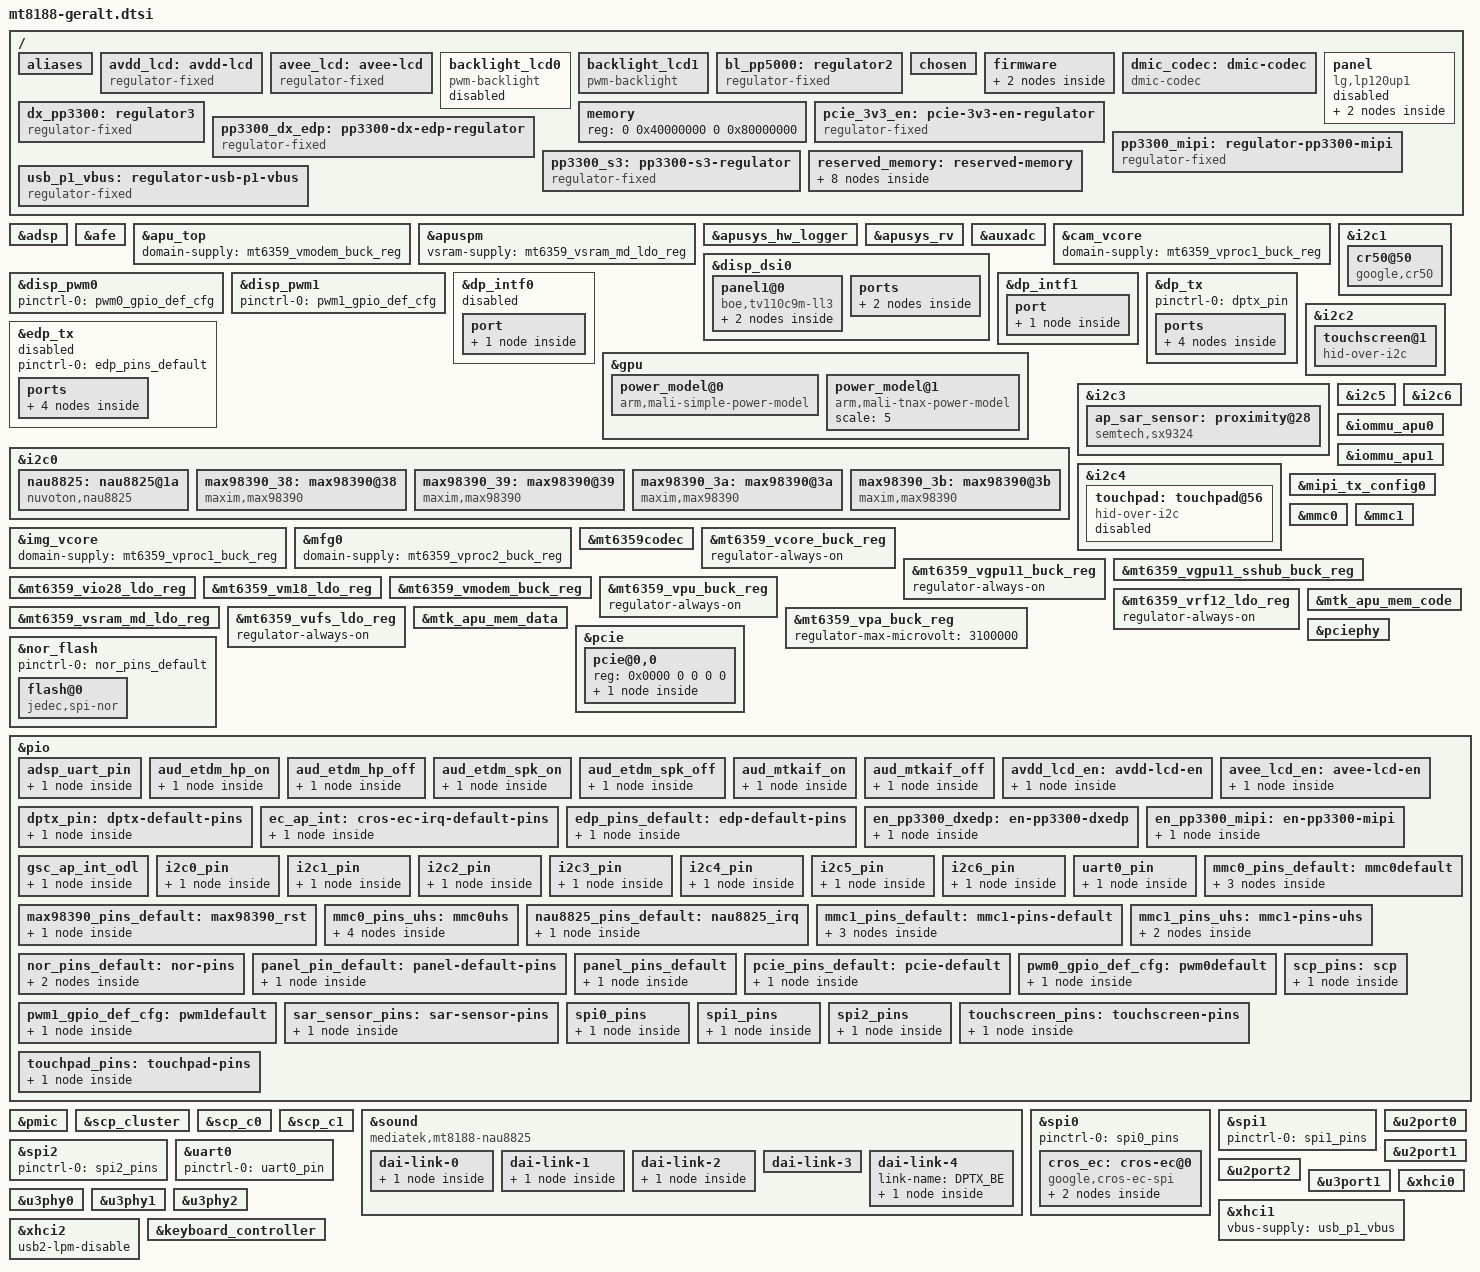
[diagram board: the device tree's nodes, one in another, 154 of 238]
// SPDX-License-Identifier: (GPL-2.0 OR MIT)
/*
 * Copyright (C) 2022 MediaTek Inc.
 */
/dts-v1/;
#include <dt-bindings/gpio/gpio.h>
#include "mt8188.dtsi"
#include "mt6359.dtsi"

/ {
	aliases {
		serial0 = &uart0;
		i2c0 = &i2c0;
		i2c1 = &i2c1;
		i2c2 = &i2c2;
		i2c3 = &i2c3;
		i2c4 = &i2c4;
		i2c5 = &i2c5;
		i2c6 = &i2c6;
		mmc0 = &mmc0;
		mmc1 = &mmc1;
	};

	avdd_lcd: avdd-lcd {
		compatible = "regulator-fixed";
		regulator-name = "avdd_lcd";
		gpio = <&pio 3 GPIO_ACTIVE_HIGH>;
		enable-active-high;
		pinctrl-names = "default";
		pinctrl-0 = <&avdd_lcd_en>;
	};

	avee_lcd: avee-lcd {
		compatible = "regulator-fixed";
		regulator-name = "avee_lcd";
		gpio = <&pio 4 GPIO_ACTIVE_HIGH>;
		enable-active-high;
		pinctrl-names = "default";
		pinctrl-0 = <&avee_lcd_en>;
		regulator-enable-ramp-delay = <10000>;
	};

	backlight_lcd0: backlight_lcd0 {
		compatible = "pwm-backlight";
		pwms = <&disp_pwm1 0 500000>;
		power-supply = <&bl_pp5000>;
		enable-gpios = <&pio 110 0>;
		brightness-levels = <0 1023>;
		num-interpolated-steps = <1023>;
		default-brightness-level = <576>;
		status = "disabled";
	};

	backlight_lcd1: backlight_lcd1 {
		compatible = "pwm-backlight";
		pwms = <&disp_pwm0 0 500000>;
		power-supply = <&bl_pp5000>;
		enable-gpios = <&pio 1 0>;
		brightness-levels = <0 1023>;
		num-interpolated-steps = <1023>;
		default-brightness-level = <576>;
		status = "okay";
	};

	bl_pp5000: regulator2 {
		compatible = "regulator-fixed";
		regulator-name = "bl_pp5000";
		regulator-min-microvolt = <5000000>;
		regulator-max-microvolt = <5000000>;
		regulator-always-on;
		regulator-boot-on;
		enable-active-high;
	};

	/* chosen */
	chosen: chosen {
		stdout-path = "serial0:115200n8";
		kaslr-seed = <0 0>;
	};

	firmware {
		optee {
			compatible = "linaro,optee-tz";
			method = "smc";
			interrupt-parent = <&gic>;
			interrupts = <GIC_SPI 547 IRQ_TYPE_LEVEL_HIGH 0>;
		};

		mtk_svp_heap {
			compatible = "mediatek,secure_heap";
			memory-region = <&secure_cma_reserved>;
		};
	};

        dmic_codec: dmic-codec {
		compatible = "dmic-codec";
		num-channels = <2>;
		wakeup-delay-ms = <50>;
	};

	dx_pp3300: regulator3 {
		compatible = "regulator-fixed";
		regulator-name = "dx_pp3300";
		regulator-min-microvolt = <3300000>;
		regulator-max-microvolt = <3300000>;
		regulator-always-on;
		regulator-boot-on;
		enable-active-high;
	};

	memory {
		device_type = "memory";
		reg = <0 0x40000000 0 0x80000000>;
	};

	panel: panel {
		compatible = "lg,lp120up1";
		status = "disabled";
		pinctrl-names = "default";
		pinctrl-0 = <&panel_pin_default>;
		backlight = <&backlight_lcd0>;
		port {
			panel_in: endpoint {
				remote-endpoint = <&edp_out>;
			};
		};
	};

	pcie_3v3_en: pcie-3v3-en-regulator {
		compatible = "regulator-fixed";
		regulator-name = "pcie_3v3_en";
		regulator-always-on;
		gpio = <&pio 12 0>;
		enable-active-high;
	};

	pp3300_dx_edp: pp3300-dx-edp-regulator {
		compatible = "regulator-fixed";
		regulator-name = "pp3300_dx_edp";
		pinctrl-names = "default";
		pinctrl-0 = <&en_pp3300_dxedp>;
		enable-active-high;
		regulator-boot-on;
		gpio = <&pio 27 GPIO_ACTIVE_HIGH>;
		vin-supply = <&dx_pp3300>;
	};

	pp3300_mipi: regulator-pp3300-mipi {
		compatible = "regulator-fixed";
		regulator-name = "pp3300_mipi";
		regulator-min-microvolt = <3300000>;
		regulator-max-microvolt = <3300000>;
		regulator-always-on;
		regulator-boot-on;
		enable-active-high;
	};

	pp3300_s3: pp3300-s3-regulator {
		compatible = "regulator-fixed";
		regulator-name = "pp3300_s3";
		pinctrl-names = "default";
		pinctrl-0 = <&en_pp3300_mipi>;
		enable-active-high;
		regulator-boot-on;
		gpio = <&pio 144 GPIO_ACTIVE_HIGH>;
		vin-supply = <&pp3300_mipi>;
	};

	/*
	 * The reserved memory space address and size MUST be in line with the
	 * EMI PMU configuration in the firmware.
	 */
	reserved_memory: reserved-memory {
		#address-cells = <2>;
		#size-cells = <2>;
		ranges;

		scp_mem_reserved: scp_mem_region {
			compatible = "shared-dma-pool";
			reg = <0 0x50000000 0 0x800000>;
			no-map;
		};

		apu_reserve_memory: apu-reserve-memory {
			compatible = "shared-dma-pool";
			reg = <0 0x55000000 0 0x1400000>;
		};

		adsp_mem_reserved: adsp_mem_region {
			compatible = "mediatek,adsp-reserved-memory";
			reg = <0 0x60000000 0 0xF00000>;
			no-map;
		};

		afe_dma_mem_reserved: snd_dma_mem_region {
			compatible = "shared-dma-pool";
			reg = <0 0x60F00000 0 0x100000>;
			no-map;
		};

		adsp_dma_mem_reserved: adsp_dma_mem_region {
			compatible = "shared-dma-pool";
			reg = <0 0x61000000 0 0x100000>;
			no-map;
		};

		scp_dual_mem_reserved: scp-dual-mem-region {
			compatible = "shared-dma-pool";
			reg = <0 0x70000000 0 0x0A000000>;
			no-map;
		};

		scp_isp_cma_reserved: scp-isp-cma-region {
			compatible = "shared-dma-pool";
			reg = <0 0x7A000000 0 0x05000000>;
			reusable;
		};

		secure_cma_reserved: secure_cma_region {
			compatible = "mediatek,dynamic-restricted-region";
			reg = <0 0x7F000000 0 0x400000>;
			reusable;
		};
	};

	usb_p1_vbus: regulator-usb-p1-vbus {
		compatible = "regulator-fixed";
		regulator-name = "vbus0";
		regulator-min-microvolt = <5000000>;
		regulator-max-microvolt = <5000000>;
		enable-active-high;
		gpio = <&pio 150 GPIO_ACTIVE_HIGH>;
	};
};

&adsp {
	memory-region = <&adsp_dma_mem_reserved>,
		<&adsp_mem_reserved>;
	pinctrl-names = "default";
	pinctrl-0 = <&adsp_uart_pin>;
	status = "okay";
};

&afe {
	memory-region = <&afe_dma_mem_reserved>;
	mediatek,etdm-out1-cowork-source = <0>; /* in1 */
	mediatek,etdm-in2-cowork-source = <3>; /* out2 */
	status = "okay";
};

&apu_top {
	domain-supply = <&mt6359_vmodem_buck_reg>;
};

&apuspm {
	vsram-supply = <&mt6359_vsram_md_ldo_reg>;
	status = "okay";
};

&apusys_hw_logger {
	status = "okay";
};

&apusys_rv {
	status = "okay";
};

&auxadc {
	status = "okay";
};

&cam_vcore {
	domain-supply = <&mt6359_vproc1_buck_reg>;
};

&disp_dsi0 {
	#address-cells = <1>;
	#size-cells = <0>;
	status = "okay";

	panel1@0 {
		compatible = "boe,tv110c9m-ll3";
		reg = <0>;
		enable-gpios = <&pio 25 0>;
		avdd-supply = <&avdd_lcd>;
		avee-supply = <&avee_lcd>;
		pinctrl-names = "default";
		pinctrl-0 = <&panel_pins_default>;
		pp1800-supply = <&mt6359_vm18_ldo_reg>;
		backlight = <&backlight_lcd1>;
		rotation = <270>;
		status = "okay";

		port {
			panel1_in: endpoint {
				remote-endpoint = <&dsi_out>;
			};
		};
	};

	ports {
		port {
			dsi_out: endpoint {
				remote-endpoint = <&panel1_in>;
			};
		};
	};
};

&disp_pwm0 {
	pinctrl-names = "default";
	pinctrl-0 = <&pwm0_gpio_def_cfg>;
	status = "okay";
};

&disp_pwm1 {
	pinctrl-names = "default";
	pinctrl-0 = <&pwm1_gpio_def_cfg>;
	status = "okay";
};

&dp_intf0 {
	status = "disabled";

	port {
		dp_intf0_out: endpoint {
			remote-endpoint = <&edp_in>;
		};
	};
};

&dp_intf1 {
	status = "okay";

	port {
		dp_intf1_out: endpoint {
			remote-endpoint = <&dptx_in>;
		};
	};
};

&dp_tx {
	status = "okay";

	pinctrl-names = "default";
	pinctrl-0 = <&dptx_pin>;

	ports {
		#address-cells = <1>;
		#size-cells = <0>;

		port@0 {
			reg = <0>;
			dptx_in: endpoint {
				remote-endpoint = <&dp_intf1_out>;
			};
		};

		port@1 {
			reg = <1>;
			dptx_out: endpoint {
				data-lanes = <0 1 2 3>;
			};
		};
	};
};

&edp_tx {
	status = "disabled";

	pinctrl-names = "default";
	pinctrl-0 = <&edp_pins_default>;

	ports {
		#address-cells = <1>;
		#size-cells = <0>;

		port@0 {
			reg = <0>;
			edp_in: endpoint {
				remote-endpoint = <&dp_intf0_out>;
			};
		};

		port@1 {
			reg = <1>;
			edp_out: endpoint {
				remote-endpoint = <&panel_in>;
				data-lanes = <0 1 2 3>;
			};
		};
	};
};

&gpu {
	supply-names = "mali","mali_sram";
	mali-supply = <&mt6359_vproc2_buck_reg>;
	mali_sram-supply = <&mt6359_vsram_others_ldo_reg>;
	operating-points-v2 = <&gpu_opp_table>;
	volt-bin-mapping = <3 4 5 6>;

	power_model@0 {
		compatible = "arm,mali-simple-power-model";
		static-coefficient = <2427750>;
		dynamic-coefficient = <4687>;
		ts = <20000 2000 (-20) 2>;
		thermal-zone = "soc_max";
	};

	power_model@1 {
		compatible = "arm,mali-tnax-power-model";
		scale = <5>;
	};
};

&i2c0 {
	pinctrl-names = "default";
	pinctrl-0 = <&i2c0_pin>;
	clock-frequency = <400000>;
	status = "okay";

	nau8825: nau8825@1a {
		#sound-dai-cells = <0>;
		compatible = "nuvoton,nau8825";
		reg = <0x1a>;
		interrupt-parent = <&pio>;
		interrupts = <108 IRQ_TYPE_LEVEL_LOW>;
		pinctrl-names = "default";
		pinctrl-0 = <&nau8825_pins_default>;

		nuvoton,jkdet-enable;
		nuvoton,jkdet-polarity = <1>;
		nuvoton,vref-impedance = <2>;
		nuvoton,micbias-voltage = <6>;
		nuvoton,sar-hysteresis = <1>;
		nuvoton,sar-voltage = <6>;
		nuvoton,sar-compare-time = <0>;
		nuvoton,sar-sampling-time = <0>;
		nuvoton,short-key-debounce = <2>;
		nuvoton,jack-insert-debounce = <7>;
		nuvoton,jack-eject-debounce = <7>;
		nuvoton,adc-delay-ms = <300>;
		status = "okay";
	};

	max98390_38: max98390@38 {
		#sound-dai-cells = <0>;
		compatible = "maxim,max98390";
		reg = <0x38>;
		sound-name-prefix = "Rear Right";
		reset-gpios = <&pio 118 1>;
		pinctrl-names = "default";
		pinctrl-0 = <&max98390_pins_default>;
		status = "okay";
	};

	max98390_39: max98390@39 {
		#sound-dai-cells = <0>;
		compatible = "maxim,max98390";
		reg = <0x39>;
		sound-name-prefix = "Rear Left";
		status = "okay";
	};

	max98390_3a: max98390@3a {
		#sound-dai-cells = <0>;
		compatible = "maxim,max98390";
		reg = <0x3A>;
		sound-name-prefix = "Front Left";
		status = "okay";
	};

	max98390_3b: max98390@3b {
		#sound-dai-cells = <0>;
		compatible = "maxim,max98390";
		reg = <0x3B>;
		sound-name-prefix = "Front Right";
		status = "okay";
	};
};

&i2c1 {
	pinctrl-names = "default";
	pinctrl-0 = <&i2c1_pin>;
	clock-frequency = <400000>;
	status = "okay";

	cr50@50 {
		compatible = "google,cr50";
		reg = <0x50>;
		interrupt-parent = <&pio>;
		interrupts = <0 IRQ_TYPE_EDGE_RISING>;
		pinctrl-names = "default";
		pinctrl-0 = <&gsc_ap_int_odl>;
	};
};

&i2c2 {
	pinctrl-names = "default";
	pinctrl-0 = <&i2c2_pin>;
	clock-frequency = <400000>;
	status = "okay";

	touchscreen@1 {
		status = "okay";
		compatible = "hid-over-i2c";
		reg = <0x1>;
		interrupt-parent = <&pio>;
		interrupts = <143 IRQ_TYPE_EDGE_FALLING>;
		pinctrl-names = "default";
		pinctrl-0 = <&touchscreen_pins>;
		vdd-supply = <&pp3300_s3>;
		vddl-supply = <&mt6359_vm18_ldo_reg>;
		post-power-on-delay-ms = <500>;
		hid-descr-addr = <0x0001>;
	};
};

&i2c3 {
	pinctrl-names = "default";
	pinctrl-0 = <&i2c3_pin>;
	clock-frequency = <400000>;
	status = "okay";

	ap_sar_sensor: proximity@28 {
		compatible = "semtech,sx9324";
		reg = <0x28>;
		#io-channel-cells = <1>;
		pinctrl-names = "default";
		pinctrl-0 = <&sar_sensor_pins>;
		interrupt-parent = <&pio>;
		interrupts = <88 IRQ_TYPE_LEVEL_LOW>;
		vdd-supply = <&mt6359_vio18_ldo_reg>;
		svdd-supply = <&mt6359_vio18_ldo_reg>;
	};
};

&i2c4 {
	pinctrl-names = "default";
	pinctrl-0 = <&i2c4_pin>;
	clock-frequency = <400000>;
	status = "okay";

	touchpad: touchpad@56 {
		status = "disabled";
		compatible = "hid-over-i2c";
		reg = <0x56>;
		interrupt-parent = <&pio>;
		interrupts = <148 IRQ_TYPE_LEVEL_LOW>;
		pinctrl-names = "default";
		pinctrl-0 = <&touchpad_pins>;
		hid-descr-addr = <0x0001>;
		wakeup-source;
	};
};

&i2c5 {
	pinctrl-names = "default";
	pinctrl-0 = <&i2c5_pin>;
	clock-frequency = <400000>;
	status = "okay";
};

&i2c6 {
	pinctrl-names = "default";
	pinctrl-0 = <&i2c6_pin>;
	clock-frequency = <400000>;
	status = "okay";
};

&img_vcore {
	domain-supply = <&mt6359_vproc1_buck_reg>;
};

&iommu_apu0 {
	status = "okay";
};

&iommu_apu1 {
	status = "okay";
};

&mfg0 {
	domain-supply = <&mt6359_vproc2_buck_reg>;
};

&mipi_tx_config0 {
	status = "okay";
};

&mmc0 {
	status = "okay";
	pinctrl-names = "default", "state_uhs";
	pinctrl-0 = <&mmc0_pins_default>;
	pinctrl-1 = <&mmc0_pins_uhs>;
	bus-width = <8>;
	max-frequency = <200000000>;
	cap-mmc-highspeed;
	mmc-hs200-1_8v;
	mmc-hs400-1_8v;
	supports-cqe;
	cap-mmc-hw-reset;
	no-sdio;
	no-sd;
	hs400-ds-delay = <0x1481b>;
	vmmc-supply = <&mt6359_vemc_1_ldo_reg>;
	vqmmc-supply = <&mt6359_vufs_ldo_reg>;
	non-removable;
};

&mmc1 {
	status = "okay";
	pinctrl-names = "default", "state_uhs";
	pinctrl-0 = <&mmc1_pins_default>;
	pinctrl-1 = <&mmc1_pins_uhs>;
	bus-width = <4>;
	max-frequency = <200000000>;
	cap-sd-highspeed;
	sd-uhs-sdr50;
	sd-uhs-sdr104;
	no-mmc;
	no-sdio;
	cd-gpios = <&pio 107 GPIO_ACTIVE_LOW>;
	vmmc-supply = <&mt6359_vpa_buck_reg>;
	vqmmc-supply = <&mt6359_vsim1_ldo_reg>;
};

&mt6359codec {
	mediatek,dmic-mode = <1>; /* one-wire */
	mediatek,mic-type-0 = <2>; /* DMIC */
	mediatek,mic-type-2 = <2>; /* DMIC */
};

&mt6359_vcore_buck_reg {
	regulator-always-on;
};

&mt6359_vgpu11_buck_reg {
	regulator-always-on;
};

&mt6359_vgpu11_sshub_buck_reg {
	regulator-always-on;
	regulator-min-microvolt = <550000>;
	regulator-max-microvolt = <550000>;
};

&mt6359_vio28_ldo_reg {
	/delete-property/ regulator-always-on;
};

&mt6359_vm18_ldo_reg {
	/delete-property/ regulator-always-on;
};

&mt6359_vmodem_buck_reg {
	regulator-min-microvolt = <775000>;
	regulator-max-microvolt = <775000>;
};

&mt6359_vpu_buck_reg {
	regulator-always-on;
};

&mt6359_vrf12_ldo_reg {
	regulator-always-on;
};

&mt6359_vsram_md_ldo_reg {
	regulator-min-microvolt = <800000>;
	regulator-max-microvolt = <800000>;
};

&mt6359_vufs_ldo_reg {
	regulator-always-on;
};

&mt6359_vpa_buck_reg {
	regulator-max-microvolt = <3100000>;
};

&mtk_apu_mem_code {
	status = "okay";
};

&mtk_apu_mem_data {
	status = "okay";
};

&nor_flash {
	status = "okay";
	pinctrl-names = "default";
	pinctrl-0 = <&nor_pins_default>;

	flash@0 {
		compatible = "jedec,spi-nor";
		reg = <0>;
		spi-max-frequency = <52000000>;
	};
};

&pcie {
	pinctrl-names = "default";
	pinctrl-0 = <&pcie_pins_default>;
	pcie3v3-supply = <&pcie_3v3_en>;
	pcie1v8-supply = <&mt6359_vcn18_ldo_reg>;
	dsc-reset-gpios = <&pio 145 1>;
	status = "okay";

	pcie@0,0 {
		#address-cells = <3>;
		#size-cells = <2>;
		reg = <0x0000 0 0 0 0>;
		wifi: pcie@1,0 {
			reg = <0x0000 0 0 0 0>;
			wakeup-source;
		};
	};
};

&pciephy {
	status = "okay";
};

&pio {
	pinctrl-names = "default";

	gpio-line-names =
		"GSC_AP_INT_ODL",
		"AP_DISP_BKLTEN",
		"",
		"EN_PPVAR_MIPI_DISP",
		"EN_PPVAR_MIPI_DISP_150MA",
		"TCHSCR_RST_1V8_L",
		"TCHSRC_REPORT_DISABLE",
		"",
		"",
		"",
		"",
		"I2S_SPKR_DATAOUT",
		"EN_PP3300_WLAN_X",
		"WIFI_KILL_1V8_L",
		"BT_KILL_1V8_L",
		"AP_FLASH_WP_L",
		"",
		"EDP_HDP_1V8",
		"WCAM_PWDN_L",
		"WCAM_RST_L",
		"UCAM_PWDM_L",
		"UCAM_RST_L",
		"WCAM_24M_CLK",
		"UCAM_24M_CLK",
		"MT6319_INT",
		"DISP_RST_1V8_L",
		"DSIO_DSI_TE",
		"EN_PP3300_EDP_DISP_X",
		"TP",
		"MIPI_BL_PWM_1V8",
		"EDP_BL_PWM_1V8",
		"UART_AP_TX_GSC_RX",
		"UART_GSC_TX_AP_RX",
		"UART_SSPM_TX_DBGCON_RX",
		"UART_DBGCON_TX_SSPM_RX",
		"UART_ADSP_TX_DBGCON_RX",
		"UART_DBGCON_TX_ADSP_RX",
		"JTAG_AP_TMS",
		"JTAG_AP_TCK",
		"JTAG_AP_TDI",
		"JTAG_AP_TDO",
		"JTAG_AP_TRST",
		"AP_KPCOLO",
		"TP",
		"BEEP_ON_OD",
		"TP",
		"EC_AP_HPD_OD",
		"PCIE_WAKE_1V8_ODL",
		"PCIE_RST_1V8_L",
		"PCIE_CLKREQ_1V8_ODL",
		"MIPI_DISP_ID0",
		"MIPI_DISP_ID1",
		"",
		"",
		"",
		"AP_I2C_AUD_SCL_1V8",
		"AP_I2C_AUD_SDA_1V8",
		"AP_I2C_TPM_SCL_1V8",
		"AP_I2C_TPM_SDA_1V8",
		"AP_I2C_TCHSCR_SCL_1V8",
		"AP_I2C_TCHSCR_SDA_1V8",
		"AP_I2C_PMIC_SAR_SCL_1V8",
		"AP_I2C_PMIC_SAR_SDA_1V8",
		"AP_I2C_EC_HID_KB_SCL_1V8",
		"AP_I2C_EC_HID_KB_SDA_1V8",
		"AP_I2C_UCAM_SCL_1V8",
		"AP_I2C_UCAM_SDA_1V8",
		"AP_I2C_WCAM_SCL_1V8",
		"AP_I2C_WCAM_SDA_1V8",
		"SPI_AP_CS_EC_L",
		"SPI_AP_CLK_EC",
		"SPI_AP_DO_EC_DI",
		"SPI_AP_DI_EC_DO",
		"TP",
		"TP",
		"SPI_AP_CS_TCHSCR_L",
		"SPI_AP_CLK_TCHSCR",
		"SPI_AP_DO_TCHSCR_DI",
		"SPI_AP_DI_TCHSCR_DO",
		"TP",
		"TP",
		"TP",
		"TP",
		"",
		"",
		"",
		"TP",
		"",
		"SAR_INT_ODL",
		"",
		"",
		"",
		"PWRAP_SPI_CS_L",
		"PWRAP_SPI_CK",
		"PWRAP_SPI_MOSI",
		"PWRAP_SPI_MISO",
		"SRCLKENA0",
		"SRCLKENA1",
		"SCP_VREQ_VAO",
		"AP_RTC_CLK32K",
		"AP_PMIC_WDTRST_L",
		"AUD_CLK_MOSI",
		"AUD_SYNC_MOSI",
		"AUD_DAT_MOSI0",
		"AUD_DAT_MOSI1",
		"AUD_DAT_MISO0",
		"AUD_DAT_MISO1",
		"SD_CD_ODL",
		"HP_INT_ODL",
		"SPKR_INT_ODL",
		"I2S_HP_DATAIN",
		"EN_SPKR",
		"I2S_SPKR_MCLK",
		"I2S_SPKR_BCLK",
		"I2S_HP_MCLK",
		"I2S_HP_BCLK",
		"I2S_HP_LRCK",
		"I2S_HP_DATAOUT",
		"RST_SPKR_L",
		"I2S_SPKR_LRCK",
		"I2S_SPKR_DATAIN",
		"",
		"",
		"",
		"",
		"SPI_AP_CLK_ROM",
		"SPI_AP_CS_ROM_L",
		"SPI_AP_DO_ROM_DI",
		"SPI_AP_DI_ROM_DO",
		"TP",
		"TP",
		"",
		"",
		"",
		"",
		"",
		"",
		"",
		"",
		"EN_PP2800A_UCAM_X",
		"EN_PP1200_UCAM_X",
		"EN_PP2800A_WCAM_X",
		"EN_PP1100_WCAM_X",
		"TCHSCR_INI_1V8_L",
		"EN_PP300_MIPI_TCHSRC_X",
		"MT7921_PMU_EN_1V8",
		"EN_PP3300_EDP_TCHSCR_X",
		"AP_EC_WARM_RST_REQ",
		"EC_AP_HID_INT_ODL",
		"EC_AP_INT_ODL",
		"AP_XHCI_INIT_DONE",
		"EMMC_DAT7",
		"EMMC_DAT6",
		"EMMC_DAT5",
		"EMMC_DAT4",
		"EMMC_RST_L",
		"EMMC_CMD",
		"EMMC_CLK",
		"EMMC_DAT3",
		"EMMC_DAT2",
		"EMMC_DAT1",
		"EMMC_DAT0",
		"EMMC_DSL",
		"SD_CMD",
		"SD_CLK",
		"SD_DAT0",
		"SD_DAT1",
		"SD_DAT2",
		"SD_DAT3",
		"",
		"",
		"USB3_HUB_RST_L",
		"EC_AP_RSVD0_ODL",
		"",
		"",
		"SPMI_SCL",
		"SPMI_SDA";

	adsp_uart_pin: adsp_uart_pin {
		adsp_uart_pins {
			pinmux = <PINMUX_GPIO35__FUNC_O_ADSP_UTXD0>,
				 <PINMUX_GPIO36__FUNC_I1_ADSP_URXD0>;
		};
	};

	aud_etdm_hp_on: aud_etdm_hp_on {
		pins-cmd-dat {
			pinmux = <PINMUX_GPIO110__FUNC_I0_I2SIN_D0>,
				 <PINMUX_GPIO115__FUNC_B0_I2SO2_BCK>,
				 <PINMUX_GPIO116__FUNC_B0_I2SO2_WS>,
				 <PINMUX_GPIO117__FUNC_O_I2SO2_D0>;
		};
	};

	aud_etdm_hp_off: aud_etdm_hp_off {
		pins-cmd-dat {
			pinmux = <PINMUX_GPIO110__FUNC_B_GPIO110>,
				 <PINMUX_GPIO115__FUNC_B_GPIO115>,
				 <PINMUX_GPIO116__FUNC_B_GPIO116>,
				 <PINMUX_GPIO117__FUNC_B_GPIO117>;
			bias-pull-down;
			input-enable;
		};
	};

	aud_etdm_spk_on: aud_etdm_spk_on {
		pins-cmd-dat {
			pinmux = <PINMUX_GPIO11__FUNC_O_I2SO1_D0>,
				 <PINMUX_GPIO113__FUNC_B0_TDMIN_BCK>,
				 <PINMUX_GPIO119__FUNC_B0_TDMIN_LRCK>,
				 <PINMUX_GPIO120__FUNC_I0_TDMIN_DI>;
		};
	};

	aud_etdm_spk_off: aud_etdm_spk_off {
		pins-cmd-dat {
			pinmux = <PINMUX_GPIO11__FUNC_B_GPIO11>,
				 <PINMUX_GPIO113__FUNC_B_GPIO113>,
				 <PINMUX_GPIO119__FUNC_B_GPIO119>,
				 <PINMUX_GPIO120__FUNC_B_GPIO120>;
			bias-pull-down;
			input-enable;
		};
	};

	aud_mtkaif_on: aud_mtkaif_on {
		pins_cmd_dat {
			pinmux = <PINMUX_GPIO101__FUNC_O_AUD_CLK_MOSI>,
				 <PINMUX_GPIO102__FUNC_O_AUD_SYNC_MOSI>,
				 <PINMUX_GPIO103__FUNC_O_AUD_DAT_MOSI0>,
				 <PINMUX_GPIO104__FUNC_O_AUD_DAT_MOSI1>,
				 <PINMUX_GPIO105__FUNC_I0_AUD_DAT_MISO0>,
				 <PINMUX_GPIO106__FUNC_I0_AUD_DAT_MISO1>;
		};
	};

	aud_mtkaif_off: aud_mtkaif_off {
		pins_cmd_dat {
			pinmux = <PINMUX_GPIO101__FUNC_B_GPIO101>,
				 <PINMUX_GPIO102__FUNC_B_GPIO102>,
				 <PINMUX_GPIO103__FUNC_B_GPIO103>,
				 <PINMUX_GPIO104__FUNC_B_GPIO104>,
				 <PINMUX_GPIO105__FUNC_B_GPIO105>,
				 <PINMUX_GPIO106__FUNC_B_GPIO106>;
			bias-pull-down;
			input-enable;
		};
	};

	avdd_lcd_en: avdd-lcd-en {
		pins1 {
			pinmux = <PINMUX_GPIO3__FUNC_B_GPIO3>;
			output-low;
		};
	};

	avee_lcd_en: avee-lcd-en {
		pins1 {
			pinmux = <PINMUX_GPIO4__FUNC_B_GPIO4>;
			output-low;
		};
	};

	dptx_pin: dptx-default-pins {
		pins-cmd-dat {
			pinmux = <PINMUX_GPIO46__FUNC_I0_DP_TX_HPD>;
		};
	};

	ec_ap_int: cros-ec-irq-default-pins {
		pins1 {
			pinmux = <PINMUX_GPIO149__FUNC_B_GPIO149>;
			input-enable;
		};
	};

	edp_pins_default: edp-default-pins {
		pins-cmd-dat {
			pinmux = <PINMUX_GPIO17__FUNC_I0_EDP_TX_HPD>;
		};
	};

	en_pp3300_dxedp: en-pp3300-dxedp {
		pins1 {
			pinmux = <PINMUX_GPIO27__FUNC_B_GPIO27>;
			output-low;
		};
	};

	en_pp3300_mipi: en-pp3300-mipi {
		pins1 {
			pinmux = <PINMUX_GPIO144__FUNC_B_GPIO144>;
			output-low;
		};
	};

	gsc_ap_int_odl: gsc_ap_int_odl {
		pin {
			pinmux = <PINMUX_GPIO0__FUNC_B_GPIO0>;
			input-enable;
		};
	};

	i2c0_pin: i2c0_pin {
		pins_bus {
			pinmux = <PINMUX_GPIO56__FUNC_B1_SDA0>,
				 <PINMUX_GPIO55__FUNC_B1_SCL0>;
		};
	};

	i2c1_pin: i2c1_pin {
		pins_bus {
			pinmux = <PINMUX_GPIO58__FUNC_B1_SDA1>,
				 <PINMUX_GPIO57__FUNC_B1_SCL1>;
		};
	};

	i2c2_pin: i2c2_pin {
		pins_bus {
			pinmux = <PINMUX_GPIO60__FUNC_B1_SDA2>,
				 <PINMUX_GPIO59__FUNC_B1_SCL2>;
			bias-disable;
			drive-strength = <MTK_DRIVE_12mA>;
		};
	};

	i2c3_pin: i2c3_pin {
		pins_bus {
			pinmux = <PINMUX_GPIO62__FUNC_B1_SDA3>,
				 <PINMUX_GPIO61__FUNC_B1_SCL3>;
		};
	};

	i2c4_pin: i2c4_pin {
		pins_bus {
			pinmux = <PINMUX_GPIO64__FUNC_B1_SDA4>,
				 <PINMUX_GPIO63__FUNC_B1_SCL4>;
		};
	};

	i2c5_pin: i2c5_pin {
		pins_bus {
			pinmux = <PINMUX_GPIO66__FUNC_B1_SDA5>,
				 <PINMUX_GPIO65__FUNC_B1_SCL5>;
		};
	};

	i2c6_pin: i2c6_pin {
		pins_bus {
			pinmux = <PINMUX_GPIO68__FUNC_B1_SDA6>,
				 <PINMUX_GPIO67__FUNC_B1_SCL6>;
		};
	};

	uart0_pin: uart0_pin {
		uart0_pins {
			pinmux = <PINMUX_GPIO31__FUNC_O_UTXD0>,
				 <PINMUX_GPIO32__FUNC_I1_URXD0>;
			bias-pull-up;
		};
	};

	max98390_pins_default: max98390_rst {
		pins_rst {
			pinmux = <PINMUX_GPIO111__FUNC_B_GPIO111>;
		};
	};

	mmc0_pins_default: mmc0default {
		pins_cmd_dat {
			pinmux = <PINMUX_GPIO161__FUNC_B1_MSDC0_DAT0>,
				 <PINMUX_GPIO160__FUNC_B1_MSDC0_DAT1>,
				 <PINMUX_GPIO159__FUNC_B1_MSDC0_DAT2>,
				 <PINMUX_GPIO158__FUNC_B1_MSDC0_DAT3>,
				 <PINMUX_GPIO154__FUNC_B1_MSDC0_DAT4>,
				 <PINMUX_GPIO153__FUNC_B1_MSDC0_DAT5>,
				 <PINMUX_GPIO152__FUNC_B1_MSDC0_DAT6>,
				 <PINMUX_GPIO151__FUNC_B1_MSDC0_DAT7>,
				 <PINMUX_GPIO156__FUNC_B1_MSDC0_CMD>;
			input-enable;
			drive-strength = <MTK_DRIVE_6mA>;
			bias-pull-up = <MTK_PUPD_SET_R1R0_01>;
		};

		pins_clk {
			pinmux = <PINMUX_GPIO157__FUNC_B1_MSDC0_CLK>;
			drive-strength = <MTK_DRIVE_6mA>;
			bias-pull-down = <MTK_PUPD_SET_R1R0_10>;
		};

		pins_rst {
			pinmux = <PINMUX_GPIO155__FUNC_O_MSDC0_RSTB>;
			drive-strength = <MTK_DRIVE_6mA>;
			bias-pull-up = <MTK_PUPD_SET_R1R0_01>;
		};
	};

	mmc0_pins_uhs: mmc0uhs {
		pins_cmd_dat {
			pinmux = <PINMUX_GPIO161__FUNC_B1_MSDC0_DAT0>,
				 <PINMUX_GPIO160__FUNC_B1_MSDC0_DAT1>,
				 <PINMUX_GPIO159__FUNC_B1_MSDC0_DAT2>,
				 <PINMUX_GPIO158__FUNC_B1_MSDC0_DAT3>,
				 <PINMUX_GPIO154__FUNC_B1_MSDC0_DAT4>,
				 <PINMUX_GPIO153__FUNC_B1_MSDC0_DAT5>,
				 <PINMUX_GPIO152__FUNC_B1_MSDC0_DAT6>,
				 <PINMUX_GPIO151__FUNC_B1_MSDC0_DAT7>,
				 <PINMUX_GPIO156__FUNC_B1_MSDC0_CMD>;
			input-enable;
			drive-strength = <MTK_DRIVE_8mA>;
			bias-pull-up = <MTK_PUPD_SET_R1R0_01>;
		};

		pins_clk {
			pinmux = <PINMUX_GPIO157__FUNC_B1_MSDC0_CLK>;
			drive-strength = <MTK_DRIVE_8mA>;
			bias-pull-down = <MTK_PUPD_SET_R1R0_10>;
		};

		pins_ds {
			pinmux = <PINMUX_GPIO162__FUNC_B0_MSDC0_DSL>;
			drive-strength = <MTK_DRIVE_8mA>;
			bias-pull-down = <MTK_PUPD_SET_R1R0_10>;
		};

		pins_rst {
			pinmux = <PINMUX_GPIO155__FUNC_O_MSDC0_RSTB>;
			drive-strength = <MTK_DRIVE_8mA>;
			bias-pull-up = <MTK_PUPD_SET_R1R0_01>;
		};
	};

	nau8825_pins_default: nau8825_irq {
		pins-irq {
			pinmux = <PINMUX_GPIO108__FUNC_B_GPIO108>;
			input-enable;
			};
	};

	mmc1_pins_default: mmc1-pins-default {
		pins_cmd_dat {
			pinmux = <PINMUX_GPIO163__FUNC_B1_MSDC1_CMD>,
				 <PINMUX_GPIO165__FUNC_B1_MSDC1_DAT0>,
				 <PINMUX_GPIO166__FUNC_B1_MSDC1_DAT1>,
				 <PINMUX_GPIO167__FUNC_B1_MSDC1_DAT2>,
				 <PINMUX_GPIO168__FUNC_B1_MSDC1_DAT3>;
			input-enable;
			drive-strength = <MTK_DRIVE_6mA>;
			bias-pull-up = <MTK_PUPD_SET_R1R0_01>;
		};
		pins_clk {
			pinmux = <PINMUX_GPIO164__FUNC_B1_MSDC1_CLK>;
			drive-strength = <MTK_DRIVE_6mA>;
			bias-pull-down = <MTK_PUPD_SET_R1R0_10>;
		};
		pins_insert {
			pinmux = <PINMUX_GPIO107__FUNC_B_GPIO107>;
			bias-pull-up;
		};
	};

	mmc1_pins_uhs: mmc1-pins-uhs {
		pins_cmd_dat {
			pinmux = <PINMUX_GPIO163__FUNC_B1_MSDC1_CMD>,
				 <PINMUX_GPIO165__FUNC_B1_MSDC1_DAT0>,
				 <PINMUX_GPIO166__FUNC_B1_MSDC1_DAT1>,
				 <PINMUX_GPIO167__FUNC_B1_MSDC1_DAT2>,
				 <PINMUX_GPIO168__FUNC_B1_MSDC1_DAT3>;
			input-enable;
			drive-strength = <MTK_DRIVE_10mA>;
			bias-pull-up = <MTK_PUPD_SET_R1R0_01>;
		};
		pins_clk {
			pinmux = <PINMUX_GPIO164__FUNC_B1_MSDC1_CLK>;
			drive-strength = <MTK_DRIVE_6mA>;
			bias-pull-down = <MTK_PUPD_SET_R1R0_10>;
		};
	};

	nor_pins_default: nor-pins {
		pins0 {
			pinmux = <PINMUX_GPIO127__FUNC_B0_SPINOR_IO0>,
				 <PINMUX_GPIO125__FUNC_O_SPINOR_CK>,
				 <PINMUX_GPIO128__FUNC_B0_SPINOR_IO1>;
			bias-pull-down;
		};

		pins1 {
			pinmux = <PINMUX_GPIO126__FUNC_O_SPINOR_CS>;
			bias-pull-up;
		};
	};

	panel_pin_default: panel-default-pins {
		pins-cmd-dat {
			pinmux = <PINMUX_GPIO30__FUNC_B_GPIO30>;
			output-low;
		};
	};

	panel_pins_default: panel_pins_default {
		pins_cmd_dat {
			pinmux = <PINMUX_GPIO25__FUNC_B_GPIO25>,
				 <PINMUX_GPIO1__FUNC_B_GPIO1>;
			output-low;
		};
	};

	pcie_pins_default: pcie-default {
		mux {
			pinmux = <PINMUX_GPIO47__FUNC_I1_WAKEN>,
				 <PINMUX_GPIO48__FUNC_O_PERSTN>,
				 <PINMUX_GPIO49__FUNC_B1_CLKREQN>;
		};
	};

	pwm0_gpio_def_cfg: pwm0default {
		pins_cmd_dat {
			pinmux = <PINMUX_GPIO29__FUNC_O_DISP_PWM0>;
			output-high;
		};
	};

	pwm1_gpio_def_cfg: pwm1default {
		pins_cmd_dat {
			pinmux = <PINMUX_GPIO30__FUNC_O_DISP_PWM1>;
			output-high;
		};
	};

	sar_sensor_pins: sar-sensor-pins {
		pins-irq {
			pinmux = <PINMUX_GPIO88__FUNC_B_GPIO88>;
			input-enable;
			bias-pull-up;
		};
	};

	scp_pins: scp {
		pins_scp_vreq {
			pinmux = <PINMUX_GPIO98__FUNC_O_SCP_VREQ_VAO>;
			bias-disable;
			input-enable;
		};
	};

	spi0_pins: spi0_pins {
		pins_spi {
			pinmux = <PINMUX_GPIO69__FUNC_O_SPIM0_CSB>,
				 <PINMUX_GPIO70__FUNC_O_SPIM0_CLK>,
				 <PINMUX_GPIO71__FUNC_B0_SPIM0_MOSI>,
				 <PINMUX_GPIO72__FUNC_B0_SPIM0_MISO>;
			bias-disable;
		};
	};

	spi1_pins: spi1_pins {
		pins_spi {
			pinmux = <PINMUX_GPIO75__FUNC_O_SPIM1_CSB>,
				 <PINMUX_GPIO76__FUNC_O_SPIM1_CLK>,
				 <PINMUX_GPIO77__FUNC_B0_SPIM1_MOSI>,
				 <PINMUX_GPIO78__FUNC_B0_SPIM1_MISO>;
			bias-disable;
		};
	};

	spi2_pins: spi2_pins {
		pins_spi {
			pinmux = <PINMUX_GPIO79__FUNC_O_SPIM2_CSB>,
				 <PINMUX_GPIO80__FUNC_O_SPIM2_CLK>,
				 <PINMUX_GPIO81__FUNC_B0_SPIM2_MOSI>,
				 <PINMUX_GPIO82__FUNC_B0_SPIM2_MISO>;
			bias-disable;
		};
	};

	touchscreen_pins: touchscreen-pins {
		pins-irq {
			pinmux = <PINMUX_GPIO143__FUNC_B_GPIO143>;
			input-enable;
		};
	};

	touchpad_pins: touchpad-pins {
		pins-irq {
			pinmux = <PINMUX_GPIO148__FUNC_B_GPIO148>;
			input-enable;
			bias-disable;
		};
	};
};

&pmic {
	interrupt-parent = <&pio>;
	interrupts = <222 IRQ_TYPE_LEVEL_HIGH>;
};

&scp_cluster {
	status = "okay";
};

&scp_c0 {
	firmware-name = "mediatek/mt8188/scp.img";
	pinctrl-names = "default";
	pinctrl-0 = <&scp_pins>;
	memory-region = <&scp_mem_reserved>;
	status = "okay";
};

&scp_c1 {
	firmware-name = "mediatek/mt8188/scp-dual.img";
	memory-region = <&scp_dual_mem_reserved>, <&scp_isp_cma_reserved>;
	status = "okay";
};

&sound {
	compatible = "mediatek,mt8188-nau8825";
	model = "mt8188_m98390_8825";
	mediatek,adsp = <&adsp>;
	mediatek,dai-link = "DL10_FE", "ETDM1_IN_BE", "ETDM2_IN_BE",
			"ETDM1_OUT_BE", "ETDM2_OUT_BE", "DPTX_BE", "UL_SRC_BE",
			"AFE_SOF_DL2", "AFE_SOF_DL3", "AFE_SOF_UL4", "AFE_SOF_UL5";
	pinctrl-names = "aud_etdm_hp_on",
			"aud_etdm_hp_off",
			"aud_etdm_spk_on",
			"aud_etdm_spk_off",
			"aud_mtkaif_on",
			"aud_mtkaif_off";
	pinctrl-0 = <&aud_etdm_hp_on>;
	pinctrl-1 = <&aud_etdm_hp_off>;
	pinctrl-2 = <&aud_etdm_spk_on>;
	pinctrl-3 = <&aud_etdm_spk_off>;
	pinctrl-4 = <&aud_mtkaif_on>;
	pinctrl-5 = <&aud_mtkaif_off>;
	audio-routing =
		"ETDM1_OUT", "ETDM_SPK_PIN",
		"ETDM2_OUT", "ETDM_HP_PIN",
		"ETDM1_IN", "ETDM_SPK_PIN",
		"ETDM2_IN", "ETDM_HP_PIN",
		"ADDA Capture", "MTKAIF_PIN",
		"Headphone Jack", "HPOL",
		"Headphone Jack", "HPOR",
		"MIC", "Headset Mic",
		"Left Spk", "Front Left BE_OUT",
		"Right Spk", "Front Right BE_OUT",
		"Rear Left Spk", "Rear Left BE_OUT",
		"Rear Right Spk", "Rear Right BE_OUT";
	status = "okay";

	dai-link-0 {
		link-name = "ETDM2_OUT_BE";
		mediatek,clk-provider = "cpu";
		codec {
			sound-dai = <&nau8825>;
		};
	};

	dai-link-1 {
		link-name = "ETDM2_IN_BE";
		mediatek,clk-provider = "cpu";
		codec {
			sound-dai = <&nau8825>;
		};
	};

	dai-link-2 {
		link-name = "ETDM1_OUT_BE";
		dai-format = "dsp_b";
		mediatek,clk-provider = "cpu";
		codec {
			sound-dai = <&max98390_38>,
				    <&max98390_39>,
				    <&max98390_3a>,
				    <&max98390_3b>;
		};
	};

	dai-link-3 {
		link-name = "ETDM1_IN_BE";
		dai-format = "dsp_b";
		mediatek,clk-provider = "cpu";
	};

	dai-link-4 {
		link-name = "DPTX_BE";
		codec {
			sound-dai = <&dp_tx>;
		};

	};
};

&spi0 {
	pinctrl-names = "default";
	pinctrl-0 = <&spi0_pins>;
	status = "okay";

	cros_ec: cros-ec@0 {
		compatible = "google,cros-ec-spi";
		reg = <0>;
		spi-max-frequency = <3000000>;
		interrupt-parent = <&pio>;
		interrupts = <149 IRQ_TYPE_LEVEL_LOW>;
		pinctrl-names = "default";
		pinctrl-0 = <&ec_ap_int>;

		i2c_tunnel: i2c-tunnel {
			compatible = "google,cros-ec-i2c-tunnel";
			google,remote-bus = <1>;
			#address-cells = <1>;
			#size-cells = <0>;
		};

		cbas {
			compatible = "google,cros-cbas";
			disable-whisker-input;
			hid-i2c-tp = <&touchpad>;
		};
	};
};

&spi1 {
	pinctrl-names = "default";
	pinctrl-0 = <&spi1_pins>;
	status = "okay";
};

&spi2 {
	pinctrl-names = "default";
	pinctrl-0 = <&spi2_pins>;
	status = "okay";
};

&uart0 {
	pinctrl-names = "default";
	pinctrl-0 = <&uart0_pin>;
	status = "okay";
};

&u2port0 {
	status = "okay";
};

&u2port1 {
	status = "okay";
};

&u2port2 {
	status = "okay";
};

&u3port1 {
	status = "okay";
};

&u3phy0 {
	status="okay";
};

&u3phy1 {
	status="okay";
};

&u3phy2 {
	status="okay";
};

&xhci0 {
	status = "okay";
};

&xhci1 {
	status = "okay";
	vbus-supply = <&usb_p1_vbus>;
};

&xhci2 {
	status = "okay";
	usb2-lpm-disable;
};

#include <arm/cros-ec-keyboard.dtsi>
#include <arm/cros-ec-sbs.dtsi>

&keyboard_controller {
	function-row-physmap = <
		MATRIX_KEY(0x00, 0x02, 0)	/* T1 */
		MATRIX_KEY(0x03, 0x02, 0)	/* T2 */
		MATRIX_KEY(0x02, 0x02, 0)	/* T3 */
		MATRIX_KEY(0x01, 0x02, 0)	/* T4 */
		MATRIX_KEY(0x03, 0x04, 0)	/* T5 */
		MATRIX_KEY(0x02, 0x04, 0)	/* T6 */
		MATRIX_KEY(0x01, 0x04, 0)	/* T7 */
		MATRIX_KEY(0x02, 0x09, 0)	/* T8 */
		MATRIX_KEY(0x01, 0x09, 0)	/* T9 */
		MATRIX_KEY(0x00, 0x04, 0)	/* T10 */
	>;

	linux,keymap = <
		MATRIX_KEY(0x00, 0x02, KEY_BACK)
		MATRIX_KEY(0x03, 0x02, KEY_REFRESH)
		MATRIX_KEY(0x02, 0x02, KEY_ZOOM)
		MATRIX_KEY(0x01, 0x02, KEY_SCALE)
		MATRIX_KEY(0x03, 0x04, KEY_BRIGHTNESSDOWN)
		MATRIX_KEY(0x02, 0x04, KEY_BRIGHTNESSUP)
		MATRIX_KEY(0x01, 0x04, KEY_MICMUTE)
		MATRIX_KEY(0x02, 0x09, KEY_MUTE)
		MATRIX_KEY(0x01, 0x09, KEY_VOLUMEDOWN)
		MATRIX_KEY(0x00, 0x04, KEY_VOLUMEUP)
		CROS_STD_MAIN_KEYMAP
	>;
};
